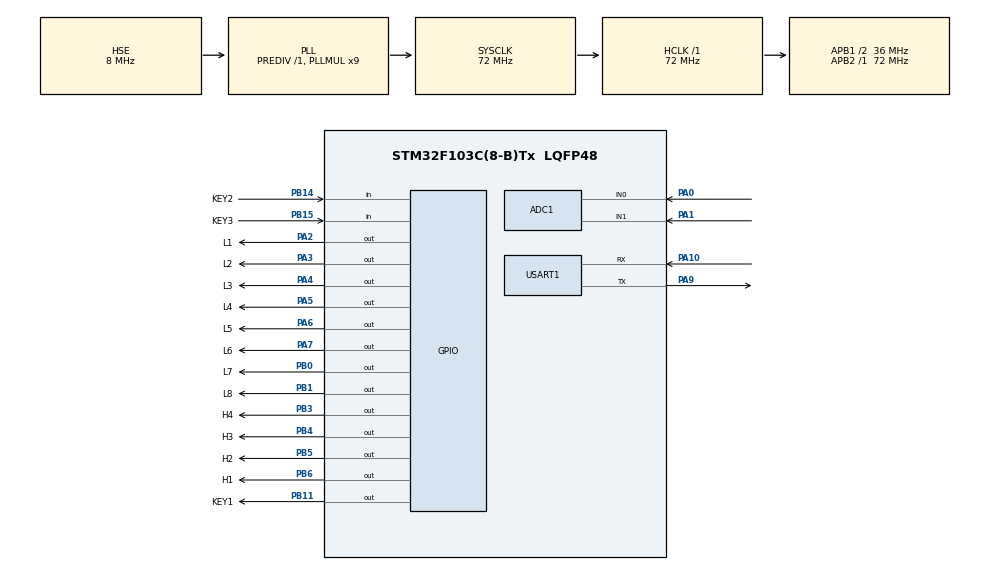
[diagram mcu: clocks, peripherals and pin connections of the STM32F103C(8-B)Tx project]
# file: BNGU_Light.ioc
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ADC1.Channel-0\#ChannelRegularConversion=ADC_CHANNEL_0
ADC1.Channel-1\#ChannelRegularConversion=ADC_CHANNEL_1
ADC1.ContinuousConvMode=DISABLE
ADC1.ExternalTrigConv=ADC_EXTERNALTRIGCONV_T3_TRGO
ADC1.NbrOfConversion=2
ADC1.NbrOfConversionFlag=1
ADC1.Rank-0\#ChannelRegularConversion=1
ADC1.Rank-1\#ChannelRegularConversion=2
ADC1.SamplingTime-0\#ChannelRegularConversion=ADC_SAMPLETIME_239CYCLES_5
ADC1.SamplingTime-1\#ChannelRegularConversion=ADC_SAMPLETIME_55CYCLES_5
ADC1.master=1
Dma.ADC1.1.Direction=DMA_PERIPH_TO_MEMORY
Dma.ADC1.1.Instance=DMA1_Channel1
Dma.ADC1.1.MemDataAlignment=DMA_MDATAALIGN_HALFWORD
Dma.ADC1.1.MemInc=DMA_MINC_ENABLE
Dma.ADC1.1.Mode=DMA_CIRCULAR
Dma.ADC1.1.PeriphDataAlignment=DMA_PDATAALIGN_HALFWORD
Dma.ADC1.1.PeriphInc=DMA_PINC_DISABLE
Dma.ADC1.1.Priority=DMA_PRIORITY_LOW
Dma.Request0=USART1_TX
Dma.Request1=ADC1
Dma.USART1_TX.0.Direction=DMA_MEMORY_TO_PERIPH
Dma.USART1_TX.0.Instance=DMA1_Channel4
Dma.USART1_TX.0.MemDataAlignment=DMA_MDATAALIGN_BYTE
Dma.USART1_TX.0.MemInc=DMA_MINC_ENABLE
Dma.USART1_TX.0.Mode=DMA_NORMAL
Dma.USART1_TX.0.PeriphDataAlignment=DMA_PDATAALIGN_BYTE
Dma.USART1_TX.0.PeriphInc=DMA_PINC_DISABLE
Dma.USART1_TX.0.Priority=DMA_PRIORITY_LOW
Mcu.Family=STM32F1
Mcu.Name=STM32F103C(8-B)Tx
Mcu.Package=LQFP48
NVIC.DMA1_Channel1_IRQn=true\:2\:0\:true\:false\:true\:false\:true\:true
NVIC.DMA1_Channel4_IRQn=true\:2\:0\:true\:false\:true\:false\:true\:true
NVIC.PriorityGroup=NVIC_PRIORITYGROUP_4
NVIC.TIM1_UP_IRQn=true\:0\:0\:false\:false\:true\:true\:true\:true
NVIC.TIM2_IRQn=true\:0\:0\:false\:false\:true\:true\:true\:true
NVIC.TIM3_IRQn=true\:1\:0\:true\:false\:true\:true\:true\:true
NVIC.USART1_IRQn=true\:3\:0\:true\:false\:true\:false\:true\:true
PA0-WKUP.Signal=ADCx_IN0
PA1.Signal=ADCx_IN1
PA10.Mode=Asynchronous
PA10.Signal=USART1_RX
PA13.Mode=Serial_Wire
PA13.Signal=SYS_JTMS-SWDIO
PA14.Mode=Serial_Wire
PA14.Signal=SYS_JTCK-SWCLK
PA2.GPIO_Label=L1
PA2.GPIO_Speed=GPIO_SPEED_FREQ_MEDIUM
PA2.Signal=GPIO_Output
PA3.GPIO_Label=L2
PA3.GPIO_Speed=GPIO_SPEED_FREQ_MEDIUM
PA3.Signal=GPIO_Output
PA4.GPIO_Label=L3
PA4.GPIO_Speed=GPIO_SPEED_FREQ_MEDIUM
PA4.Signal=GPIO_Output
PA5.GPIO_Label=L4
PA5.GPIO_Speed=GPIO_SPEED_FREQ_MEDIUM
PA5.Signal=GPIO_Output
PA6.GPIO_Label=L5
PA6.GPIO_Speed=GPIO_SPEED_FREQ_MEDIUM
PA6.Signal=GPIO_Output
PA7.GPIO_Label=L6
PA7.GPIO_Speed=GPIO_SPEED_FREQ_MEDIUM
PA7.Signal=GPIO_Output
PA9.Mode=Asynchronous
PA9.Signal=USART1_TX
PB0.GPIO_Label=L7
PB0.GPIO_Speed=GPIO_SPEED_FREQ_MEDIUM
PB0.Signal=GPIO_Output
PB1.GPIO_Label=L8
PB1.GPIO_Speed=GPIO_SPEED_FREQ_MEDIUM
PB1.Signal=GPIO_Output
PB11.GPIO_Label=KEY1
PB11.GPIO_Speed=GPIO_SPEED_FREQ_LOW
PB11.PinState=GPIO_PIN_SET
PB11.Signal=GPIO_Output
PB14.GPIO_Label=KEY2
PB14.GPIO_PuPd=GPIO_PULLUP
PB14.Signal=GPIO_Input
PB15.GPIO_Label=KEY3
PB15.GPIO_PuPd=GPIO_PULLUP
PB15.Signal=GPIO_Input
PB3.GPIO_Label=H4
PB3.GPIO_Speed=GPIO_SPEED_FREQ_MEDIUM
PB3.PinState=GPIO_PIN_SET
PB3.Signal=GPIO_Output
PB4.GPIO_Label=H3
PB4.GPIO_Speed=GPIO_SPEED_FREQ_MEDIUM
PB4.PinState=GPIO_PIN_SET
PB4.Signal=GPIO_Output
PB5.GPIO_Label=H2
PB5.GPIO_Speed=GPIO_SPEED_FREQ_MEDIUM
PB5.PinState=GPIO_PIN_SET
PB5.Signal=GPIO_Output
PB6.GPIO_Label=H1
PB6.GPIO_Speed=GPIO_SPEED_FREQ_MEDIUM
PB6.PinState=GPIO_PIN_SET
PB6.Signal=GPIO_Output
PD0-OSC_IN.Mode=HSE-External-Oscillator
PD0-OSC_IN.Signal=RCC_OSC_IN
PD1-OSC_OUT.Mode=HSE-External-Oscillator
PD1-OSC_OUT.Signal=RCC_OSC_OUT
ProjectManager.HeapSize=0x200
ProjectManager.StackSize=0x800
ProjectManager.TargetToolchain=CMake
RCC.ADCPresc=RCC_ADCPCLK2_DIV6
RCC.AHBFreq_Value=72000000
RCC.APB1CLKDivider=RCC_HCLK_DIV2
RCC.APB1Freq_Value=36000000
RCC.APB1TimFreq_Value=72000000
RCC.APB2Freq_Value=72000000
RCC.APB2TimFreq_Value=72000000
RCC.HCLKFreq_Value=72000000
RCC.PLLMUL=RCC_PLL_MUL9
RCC.PLLSourceVirtual=RCC_PLLSOURCE_HSE
RCC.SYSCLKFreq_VALUE=72000000
RCC.SYSCLKSource=RCC_SYSCLKSOURCE_PLLCLK
RCC.USBFreq_Value=72000000
SH.ADCx_IN0.0=ADC1_IN0,IN0
SH.ADCx_IN1.0=ADC1_IN1,IN1
TIM1.Period=999
TIM1.Prescaler=71
TIM2.Period=49
TIM2.Prescaler=71
TIM3.Period=99
TIM3.Prescaler=7199
TIM3.TIM_MasterOutputTrigger=TIM_TRGO_UPDATE
USART1.VirtualMode=VM_ASYNC
VP_TIM1_VS_ClockSourceINT.Mode=Internal
VP_TIM2_VS_ClockSourceINT.Mode=Internal
VP_TIM3_VS_ClockSourceINT.Mode=Internal
board=custom

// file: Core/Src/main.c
/* USER CODE BEGIN Header */
/**
  ******************************************************************************
  * @file           : main.c
  * @brief          : Main program body
  ******************************************************************************
  * @attention
  *
  * Copyright (c) 2026 STMicroelectronics.
  * All rights reserved.
  *
  * This software is licensed under terms that can be found in the LICENSE file
  * in the root directory of this software component.
  * If no LICENSE file comes with this software, it is provided AS-IS.
  *
  ******************************************************************************
  */
/* USER CODE END Header */
#include "main.h"

/* USER CODE BEGIN Includes */
#include "app.h"
/* USER CODE END Includes */

ADC_HandleTypeDef hadc1;
DMA_HandleTypeDef hdma_adc1;

TIM_HandleTypeDef htim1;
TIM_HandleTypeDef htim2;
TIM_HandleTypeDef htim3;

UART_HandleTypeDef huart1;
DMA_HandleTypeDef hdma_usart1_tx;

void SystemClock_Config(void);
static void MX_GPIO_Init(void);
static void MX_DMA_Init(void);
static void MX_USART1_UART_Init(void);
static void MX_ADC1_Init(void);
static void MX_TIM1_Init(void);
static void MX_TIM2_Init(void);
static void MX_TIM3_Init(void);

int main(void)
{

  /* MCU Configuration--------------------------------------------------------*/

  /* Reset of all peripherals, Initializes the Flash interface and the Systick. */
  HAL_Init();

  /* Configure the system clock */
  SystemClock_Config();

  /* Initialize all configured peripherals */
  MX_GPIO_Init();
  MX_DMA_Init();
  MX_USART1_UART_Init();
  MX_ADC1_Init();
  MX_TIM1_Init();
  MX_TIM2_Init();
  MX_TIM3_Init();
  /* USER CODE BEGIN 2 */
  /* 各模块初始化 + 按正确顺序启动 TIM3 / TIM2 / TIM1（实现见 App/app.c） */
  app_init();
  /* USER CODE END 2 */

  /* Infinite loop */
  while (1)
  {

    /* USER CODE BEGIN 3 */
    app_run();   /* 有 100Hz 节拍就处理一次：ADC → 自检动画 → 10Hz 遥测 */
  }
  /* USER CODE END 3 */
}

void SystemClock_Config(void)
{
  RCC_OscInitTypeDef RCC_OscInitStruct = {0};
  RCC_ClkInitTypeDef RCC_ClkInitStruct = {0};
  RCC_PeriphCLKInitTypeDef PeriphClkInit = {0};

  /** Initializes the RCC Oscillators according to the specified parameters
  * in the RCC_OscInitTypeDef structure.
  */
  RCC_OscInitStruct.OscillatorType = RCC_OSCILLATORTYPE_HSE;
  RCC_OscInitStruct.HSEState = RCC_HSE_ON;
  RCC_OscInitStruct.HSEPredivValue = RCC_HSE_PREDIV_DIV1;
  RCC_OscInitStruct.HSIState = RCC_HSI_ON;
  RCC_OscInitStruct.PLL.PLLState = RCC_PLL_ON;
  RCC_OscInitStruct.PLL.PLLSource = RCC_PLLSOURCE_HSE;
  RCC_OscInitStruct.PLL.PLLMUL = RCC_PLL_MUL9;
  if (HAL_RCC_OscConfig(&RCC_OscInitStruct) != HAL_OK)
  {
    Error_Handler();
  }

  /** Initializes the CPU, AHB and APB buses clocks
  */
  RCC_ClkInitStruct.ClockType = RCC_CLOCKTYPE_HCLK|RCC_CLOCKTYPE_SYSCLK
                              |RCC_CLOCKTYPE_PCLK1|RCC_CLOCKTYPE_PCLK2;
  RCC_ClkInitStruct.SYSCLKSource = RCC_SYSCLKSOURCE_PLLCLK;
  RCC_ClkInitStruct.AHBCLKDivider = RCC_SYSCLK_DIV1;
  RCC_ClkInitStruct.APB1CLKDivider = RCC_HCLK_DIV2;
  RCC_ClkInitStruct.APB2CLKDivider = RCC_HCLK_DIV1;

  if (HAL_RCC_ClockConfig(&RCC_ClkInitStruct, FLASH_LATENCY_2) != HAL_OK)
  {
    Error_Handler();
  }
  PeriphClkInit.PeriphClockSelection = RCC_PERIPHCLK_ADC;
  PeriphClkInit.AdcClockSelection = RCC_ADCPCLK2_DIV6;
  if (HAL_RCCEx_PeriphCLKConfig(&PeriphClkInit) != HAL_OK)
  {
    Error_Handler();
  }
}

static void MX_ADC1_Init(void)
{

  ADC_ChannelConfTypeDef sConfig = {0};

  /** Common config
  */
  hadc1.Instance = ADC1;
  hadc1.Init.ScanConvMode = ADC_SCAN_ENABLE;
  hadc1.Init.ContinuousConvMode = DISABLE;
  hadc1.Init.DiscontinuousConvMode = DISABLE;
  hadc1.Init.ExternalTrigConv = ADC_EXTERNALTRIGCONV_T3_TRGO;
  hadc1.Init.DataAlign = ADC_DATAALIGN_RIGHT;
  hadc1.Init.NbrOfConversion = 2;
  if (HAL_ADC_Init(&hadc1) != HAL_OK)
  {
    Error_Handler();
  }

  /** Configure Regular Channel
  */
  sConfig.Channel = ADC_CHANNEL_0;
  sConfig.Rank = ADC_REGULAR_RANK_1;
  sConfig.SamplingTime = ADC_SAMPLETIME_239CYCLES_5;
  if (HAL_ADC_ConfigChannel(&hadc1, &sConfig) != HAL_OK)
  {
    Error_Handler();
  }

  /** Configure Regular Channel
  */
  sConfig.Channel = ADC_CHANNEL_1;
  sConfig.Rank = ADC_REGULAR_RANK_2;
  sConfig.SamplingTime = ADC_SAMPLETIME_55CYCLES_5;
  if (HAL_ADC_ConfigChannel(&hadc1, &sConfig) != HAL_OK)
  {
    Error_Handler();
  }

}

static void MX_TIM1_Init(void)
{

  TIM_ClockConfigTypeDef sClockSourceConfig = {0};
  TIM_MasterConfigTypeDef sMasterConfig = {0};

  htim1.Instance = TIM1;
  htim1.Init.Prescaler = 71;
  htim1.Init.CounterMode = TIM_COUNTERMODE_UP;
  htim1.Init.Period = 999;
  htim1.Init.ClockDivision = TIM_CLOCKDIVISION_DIV1;
  htim1.Init.RepetitionCounter = 0;
  htim1.Init.AutoReloadPreload = TIM_AUTORELOAD_PRELOAD_DISABLE;
  if (HAL_TIM_Base_Init(&htim1) != HAL_OK)
  {
    Error_Handler();
  }
  sClockSourceConfig.ClockSource = TIM_CLOCKSOURCE_INTERNAL;
  if (HAL_TIM_ConfigClockSource(&htim1, &sClockSourceConfig) != HAL_OK)
  {
    Error_Handler();
  }
  sMasterConfig.MasterOutputTrigger = TIM_TRGO_RESET;
  sMasterConfig.MasterSlaveMode = TIM_MASTERSLAVEMODE_DISABLE;
  if (HAL_TIMEx_MasterConfigSynchronization(&htim1, &sMasterConfig) != HAL_OK)
  {
    Error_Handler();
  }

}

static void MX_TIM2_Init(void)
{

  TIM_ClockConfigTypeDef sClockSourceConfig = {0};
  TIM_MasterConfigTypeDef sMasterConfig = {0};

  htim2.Instance = TIM2;
  htim2.Init.Prescaler = 71;
  htim2.Init.CounterMode = TIM_COUNTERMODE_UP;
  htim2.Init.Period = 49;
  htim2.Init.ClockDivision = TIM_CLOCKDIVISION_DIV1;
  htim2.Init.AutoReloadPreload = TIM_AUTORELOAD_PRELOAD_DISABLE;
  if (HAL_TIM_Base_Init(&htim2) != HAL_OK)
  {
    Error_Handler();
  }
  sClockSourceConfig.ClockSource = TIM_CLOCKSOURCE_INTERNAL;
  if (HAL_TIM_ConfigClockSource(&htim2, &sClockSourceConfig) != HAL_OK)
  {
    Error_Handler();
  }
  sMasterConfig.MasterOutputTrigger = TIM_TRGO_RESET;
  sMasterConfig.MasterSlaveMode = TIM_MASTERSLAVEMODE_DISABLE;
  if (HAL_TIMEx_MasterConfigSynchronization(&htim2, &sMasterConfig) != HAL_OK)
  {
    Error_Handler();
  }

}

static void MX_TIM3_Init(void)
{

  TIM_ClockConfigTypeDef sClockSourceConfig = {0};
  TIM_MasterConfigTypeDef sMasterConfig = {0};

  htim3.Instance = TIM3;
  htim3.Init.Prescaler = 7199;
  htim3.Init.CounterMode = TIM_COUNTERMODE_UP;
  htim3.Init.Period = 99;
  htim3.Init.ClockDivision = TIM_CLOCKDIVISION_DIV1;
  htim3.Init.AutoReloadPreload = TIM_AUTORELOAD_PRELOAD_DISABLE;
  if (HAL_TIM_Base_Init(&htim3) != HAL_OK)
  {
    Error_Handler();
  }
  sClockSourceConfig.ClockSource = TIM_CLOCKSOURCE_INTERNAL;
  if (HAL_TIM_ConfigClockSource(&htim3, &sClockSourceConfig) != HAL_OK)
  {
    Error_Handler();
  }
  sMasterConfig.MasterOutputTrigger = TIM_TRGO_UPDATE;
  sMasterConfig.MasterSlaveMode = TIM_MASTERSLAVEMODE_DISABLE;
  if (HAL_TIMEx_MasterConfigSynchronization(&htim3, &sMasterConfig) != HAL_OK)
  {
    Error_Handler();
  }

}

static void MX_USART1_UART_Init(void)
{

  huart1.Instance = USART1;
  huart1.Init.BaudRate = 115200;
  huart1.Init.WordLength = UART_WORDLENGTH_8B;
  huart1.Init.StopBits = UART_STOPBITS_1;
  huart1.Init.Parity = UART_PARITY_NONE;
  huart1.Init.Mode = UART_MODE_TX_RX;
  huart1.Init.HwFlowCtl = UART_HWCONTROL_NONE;
  huart1.Init.OverSampling = UART_OVERSAMPLING_16;
  if (HAL_UART_Init(&huart1) != HAL_OK)
  {
    Error_Handler();
  }

}

static void MX_DMA_Init(void)
{

  /* DMA controller clock enable */
  __HAL_RCC_DMA1_CLK_ENABLE();

  /* DMA interrupt init */
  /* DMA1_Channel1_IRQn interrupt configuration */
  HAL_NVIC_SetPriority(DMA1_Channel1_IRQn, 2, 0);
  HAL_NVIC_EnableIRQ(DMA1_Channel1_IRQn);
  /* DMA1_Channel4_IRQn interrupt configuration */
  HAL_NVIC_SetPriority(DMA1_Channel4_IRQn, 2, 0);
  HAL_NVIC_EnableIRQ(DMA1_Channel4_IRQn);

}

static void MX_GPIO_Init(void)
{
  GPIO_InitTypeDef GPIO_InitStruct = {0};

  /* GPIO Ports Clock Enable */
  __HAL_RCC_GPIOD_CLK_ENABLE();
  __HAL_RCC_GPIOA_CLK_ENABLE();
  __HAL_RCC_GPIOB_CLK_ENABLE();

  /*Configure GPIO pin Output Level */
  HAL_GPIO_WritePin(GPIOA, L1_Pin|L2_Pin|L3_Pin|L4_Pin
                          |L5_Pin|L6_Pin, GPIO_PIN_RESET);

  /*Configure GPIO pin Output Level */
  HAL_GPIO_WritePin(GPIOB, L7_Pin|L8_Pin, GPIO_PIN_RESET);

  /*Configure GPIO pin Output Level */
  HAL_GPIO_WritePin(GPIOB, KEY1_Pin|H4_Pin|H3_Pin|H2_Pin
                          |H1_Pin, GPIO_PIN_SET);

  /*Configure GPIO pins : L1_Pin L2_Pin L3_Pin L4_Pin
                           L5_Pin L6_Pin */
  GPIO_InitStruct.Pin = L1_Pin|L2_Pin|L3_Pin|L4_Pin
                          |L5_Pin|L6_Pin;
  GPIO_InitStruct.Mode = GPIO_MODE_OUTPUT_PP;
  GPIO_InitStruct.Pull = GPIO_NOPULL;
  GPIO_InitStruct.Speed = GPIO_SPEED_FREQ_MEDIUM;
  HAL_GPIO_Init(GPIOA, &GPIO_InitStruct);

  /*Configure GPIO pins : L7_Pin L8_Pin H4_Pin H3_Pin
                           H2_Pin H1_Pin */
  GPIO_InitStruct.Pin = L7_Pin|L8_Pin|H4_Pin|H3_Pin
                          |H2_Pin|H1_Pin;
  GPIO_InitStruct.Mode = GPIO_MODE_OUTPUT_PP;
  GPIO_InitStruct.Pull = GPIO_NOPULL;
  GPIO_InitStruct.Speed = GPIO_SPEED_FREQ_MEDIUM;
  HAL_GPIO_Init(GPIOB, &GPIO_InitStruct);

  /*Configure GPIO pin : KEY1_Pin */
  GPIO_InitStruct.Pin = KEY1_Pin;
  GPIO_InitStruct.Mode = GPIO_MODE_OUTPUT_PP;
  GPIO_InitStruct.Pull = GPIO_NOPULL;
  GPIO_InitStruct.Speed = GPIO_SPEED_FREQ_LOW;
  HAL_GPIO_Init(KEY1_GPIO_Port, &GPIO_InitStruct);

  /*Configure GPIO pins : KEY2_Pin KEY3_Pin */
  GPIO_InitStruct.Pin = KEY2_Pin|KEY3_Pin;
  GPIO_InitStruct.Mode = GPIO_MODE_INPUT;
  GPIO_InitStruct.Pull = GPIO_PULLUP;
  HAL_GPIO_Init(GPIOB, &GPIO_InitStruct);

}

void Error_Handler(void)
{
  __disable_irq();
  while (1)
  {
  }
}
